VERSION "Toyota/Continental ARS510 radar bus (comma harness bus 1), frame-level. Object records need reassembly: see ars510/ and dbc/ars510_objects_vbus.dbc"

NS_ :

BS_:

BU_: RADAR CAMERA XXX

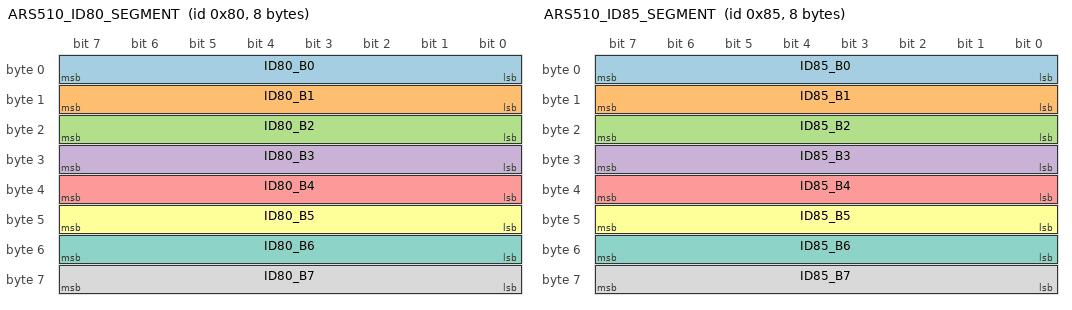
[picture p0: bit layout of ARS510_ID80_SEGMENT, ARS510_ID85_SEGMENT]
BO_ 128 ARS510_ID80_SEGMENT: 8 RADAR
 SG_ ID80_B0 : 0|8@1+ (1,0) [0|255] "raw" RADAR
 SG_ ID80_B1 : 8|8@1+ (1,0) [0|255] "raw" RADAR
 SG_ ID80_B2 : 16|8@1+ (1,0) [0|255] "raw" RADAR
 SG_ ID80_B3 : 24|8@1+ (1,0) [0|255] "raw" RADAR
 SG_ ID80_B4 : 32|8@1+ (1,0) [0|255] "raw" RADAR
 SG_ ID80_B5 : 40|8@1+ (1,0) [0|255] "raw" RADAR
 SG_ ID80_B6 : 48|8@1+ (1,0) [0|255] "raw" RADAR
 SG_ ID80_B7 : 56|8@1+ (1,0) [0|255] "raw" RADAR

BO_ 133 ARS510_ID85_SEGMENT: 8 RADAR
 SG_ ID85_B0 : 0|8@1+ (1,0) [0|255] "raw" RADAR
 SG_ ID85_B1 : 8|8@1+ (1,0) [0|255] "raw" RADAR
 SG_ ID85_B2 : 16|8@1+ (1,0) [0|255] "raw" RADAR
 SG_ ID85_B3 : 24|8@1+ (1,0) [0|255] "raw" RADAR
 SG_ ID85_B4 : 32|8@1+ (1,0) [0|255] "raw" RADAR
 SG_ ID85_B5 : 40|8@1+ (1,0) [0|255] "raw" RADAR
 SG_ ID85_B6 : 48|8@1+ (1,0) [0|255] "raw" RADAR
 SG_ ID85_B7 : 56|8@1+ (1,0) [0|255] "raw" RADAR

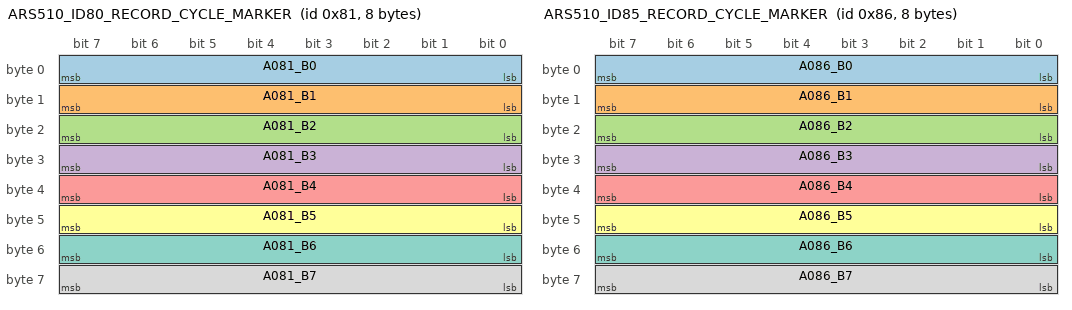
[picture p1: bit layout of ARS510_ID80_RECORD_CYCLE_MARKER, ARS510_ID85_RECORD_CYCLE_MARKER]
BO_ 129 ARS510_ID80_RECORD_CYCLE_MARKER: 8 CAMERA
 SG_ A081_B0 : 0|8@1+ (1,0) [0|255] "raw" RADAR
 SG_ A081_B1 : 8|8@1+ (1,0) [0|255] "raw" RADAR
 SG_ A081_B2 : 16|8@1+ (1,0) [0|255] "raw" RADAR
 SG_ A081_B3 : 24|8@1+ (1,0) [0|255] "raw" RADAR
 SG_ A081_B4 : 32|8@1+ (1,0) [0|255] "raw" RADAR
 SG_ A081_B5 : 40|8@1+ (1,0) [0|255] "raw" RADAR
 SG_ A081_B6 : 48|8@1+ (1,0) [0|255] "raw" RADAR
 SG_ A081_B7 : 56|8@1+ (1,0) [0|255] "raw" RADAR

BO_ 134 ARS510_ID85_RECORD_CYCLE_MARKER: 8 CAMERA
 SG_ A086_B0 : 0|8@1+ (1,0) [0|255] "raw" RADAR
 SG_ A086_B1 : 8|8@1+ (1,0) [0|255] "raw" RADAR
 SG_ A086_B2 : 16|8@1+ (1,0) [0|255] "raw" RADAR
 SG_ A086_B3 : 24|8@1+ (1,0) [0|255] "raw" RADAR
 SG_ A086_B4 : 32|8@1+ (1,0) [0|255] "raw" RADAR
 SG_ A086_B5 : 40|8@1+ (1,0) [0|255] "raw" RADAR
 SG_ A086_B6 : 48|8@1+ (1,0) [0|255] "raw" RADAR
 SG_ A086_B7 : 56|8@1+ (1,0) [0|255] "raw" RADAR

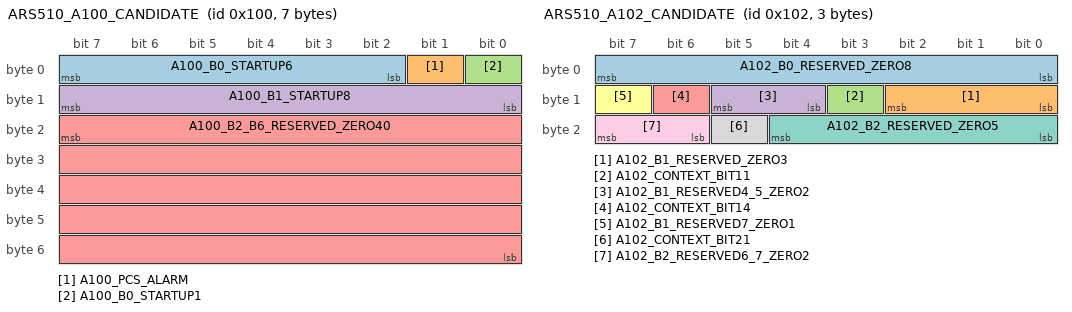
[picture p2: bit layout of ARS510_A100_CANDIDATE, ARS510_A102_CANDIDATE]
BO_ 256 ARS510_A100_CANDIDATE: 7 RADAR
 SG_ A100_B0_STARTUP6 : 7|6@0+ (1,0) [0|63] "raw" RADAR
 SG_ A100_PCS_ALARM : 1|1@0+ (1,0) [0|1] "" RADAR
 SG_ A100_B0_STARTUP1 : 0|1@0+ (1,0) [0|1] "raw" RADAR
 SG_ A100_B1_STARTUP8 : 15|8@0+ (1,0) [0|255] "raw" RADAR
 SG_ A100_B2_B6_RESERVED_ZERO40 : 23|40@0+ (1,0) [0|1099511627775] "raw" RADAR

BO_ 257 ARS510_A101_CANDIDATE: 6 CAMERA
 SG_ A101_STARTUP_STATE8 : 0|8@1+ (1,0) [0|255] "state" RADAR
 SG_ A101_B1_B5_RESERVED_ZERO40 : 15|40@0+ (1,0) [0|1099511627775] "raw" RADAR

BO_ 258 ARS510_A102_CANDIDATE: 3 CAMERA
 SG_ A102_B0_RESERVED_ZERO8 : 0|8@1+ (1,0) [0|255] "raw" RADAR
 SG_ A102_B1_RESERVED_ZERO3 : 8|3@1+ (1,0) [0|7] "raw" RADAR
 SG_ A102_CONTEXT_BIT11 : 11|1@1+ (1,0) [0|1] "state" RADAR
 SG_ A102_B1_RESERVED4_5_ZERO2 : 12|2@1+ (1,0) [0|3] "raw" RADAR
 SG_ A102_CONTEXT_BIT14 : 14|1@1+ (1,0) [0|1] "state" RADAR
 SG_ A102_B1_RESERVED7_ZERO1 : 15|1@1+ (1,0) [0|1] "raw" RADAR
 SG_ A102_B2_RESERVED_ZERO5 : 16|5@1+ (1,0) [0|31] "raw" RADAR
 SG_ A102_CONTEXT_BIT21 : 21|1@1+ (1,0) [0|1] "state" RADAR
 SG_ A102_B2_RESERVED6_7_ZERO2 : 22|2@1+ (1,0) [0|3] "raw" RADAR

BO_ 259 ARS510_A103_CANDIDATE: 2 RADAR
 SG_ A103_B0_RESERVED_ZERO8 : 0|8@1+ (1,0) [0|255] "raw" RADAR
 SG_ A103_B1_RESERVED_ZERO8 : 8|8@1+ (1,0) [0|255] "raw" RADAR

BO_ 384 ARS510_A180_CANDIDATE: 5 CAMERA
 SG_ A180_OBSERVED_CONSTANT_BE40 : 7|40@0+ (1,0) [0|1099511627775] "raw" RADAR

BO_ 400 ARS510_A190_CANDIDATE: 7 RADAR
 SG_ A190_STATUS_0_4 : 0|4@1+ (1,0) [0|15] "state" RADAR
 SG_ A190_B0_HIGH4 : 4|4@1+ (1,0) [0|15] "raw" RADAR
 SG_ A190_ACTIVE_SUMMARIES : 3|2@0+ (1,0) [0|3] "count" RADAR
 SG_ A190_B1 : 8|8@1+ (1,0) [0|255] "raw" RADAR
 SG_ A190_TIMESTAMP_US : 23|32@0+ (1,0) [0|4294967295] "us" RADAR
 SG_ A190_COUNTER_RESERVED0 : 48|4@1+ (1,0) [0|15] "raw" RADAR
 SG_ A190_COUNTER4 : 52|4@1+ (1,0) [0|15] "counter" RADAR

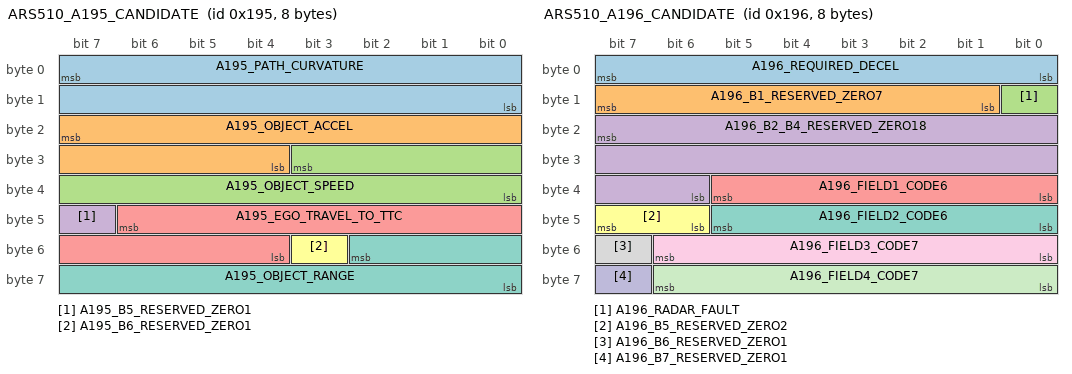
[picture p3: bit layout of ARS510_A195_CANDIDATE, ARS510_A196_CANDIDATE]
BO_ 405 ARS510_A195_CANDIDATE: 8 RADAR
 SG_ A195_PATH_CURVATURE : 7|16@0+ (7.5e-06,-0.24576) [-0.24576|0.2457525] "1/m" RADAR
 SG_ A195_OBJECT_ACCEL : 23|12@0+ (0.03125,-16) [-16|111.96875] "m/s^2" RADAR
 SG_ A195_OBJECT_SPEED : 27|12@0+ (0.0625,0) [0|255.9375] "m/s" RADAR
 SG_ A195_B5_RESERVED_ZERO1 : 47|1@0+ (1,0) [0|1] "raw" RADAR
 SG_ A195_EGO_TRAVEL_TO_TTC : 46|11@0+ (0.05,0) [0|102.35] "m" RADAR
 SG_ A195_B6_RESERVED_ZERO1 : 51|1@0+ (1,0) [0|1] "raw" RADAR
 SG_ A195_OBJECT_RANGE : 50|11@0+ (0.05,0) [0|102.35] "m" RADAR

BO_ 406 ARS510_A196_CANDIDATE: 8 RADAR
 SG_ A196_REQUIRED_DECEL : 7|8@0- (0.095,0) [-12.16|12.065] "m/s^2" RADAR
 SG_ A196_B1_RESERVED_ZERO7 : 15|7@0+ (1,0) [0|127] "raw" RADAR
 SG_ A196_RADAR_FAULT : 8|1@0+ (1,0) [0|1] "" RADAR
 SG_ A196_B2_B4_RESERVED_ZERO18 : 23|18@0+ (1,0) [0|262143] "raw" RADAR
 SG_ A196_FIELD1_CODE6 : 37|6@0+ (1,0) [0|63] "code" RADAR
 SG_ A196_B5_RESERVED_ZERO2 : 47|2@0+ (1,0) [0|3] "raw" RADAR
 SG_ A196_FIELD2_CODE6 : 45|6@0+ (1,0) [0|63] "code" RADAR
 SG_ A196_B6_RESERVED_ZERO1 : 55|1@0+ (1,0) [0|1] "raw" RADAR
 SG_ A196_FIELD3_CODE7 : 54|7@0+ (1,0) [0|127] "code" RADAR
 SG_ A196_B7_RESERVED_ZERO1 : 63|1@0+ (1,0) [0|1] "raw" RADAR
 SG_ A196_FIELD4_CODE7 : 62|7@0+ (1,0) [0|127] "code" RADAR

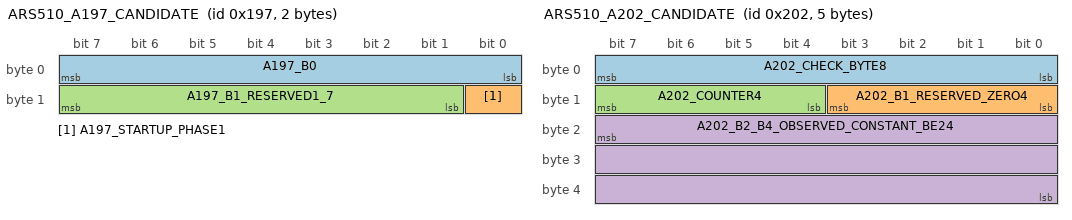
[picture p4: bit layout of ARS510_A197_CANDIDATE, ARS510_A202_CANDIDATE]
BO_ 407 ARS510_A197_CANDIDATE: 2 CAMERA
 SG_ A197_B0 : 0|8@1+ (1,0) [0|255] "raw" RADAR
 SG_ A197_STARTUP_PHASE1 : 8|1@1+ (1,0) [0|1] "state" RADAR
 SG_ A197_B1_RESERVED1_7 : 9|7@1+ (1,0) [0|127] "raw" RADAR

BO_ 408 ARS510_A198_CANDIDATE: 1 RADAR
 SG_ A198_OBSERVED_CONSTANT_BE8 : 7|8@0+ (1,0) [0|255] "raw" RADAR

BO_ 514 ARS510_A202_CANDIDATE: 5 RADAR
 SG_ A202_CHECK_BYTE8 : 0|8@1+ (1,0) [0|255] "debug" RADAR
 SG_ A202_B1_RESERVED_ZERO4 : 8|4@1+ (1,0) [0|15] "raw" RADAR
 SG_ A202_COUNTER4 : 12|4@1+ (1,0) [0|15] "counter" RADAR
 SG_ A202_B2_B4_OBSERVED_CONSTANT_BE24 : 23|24@0+ (1,0) [0|16777215] "raw" RADAR

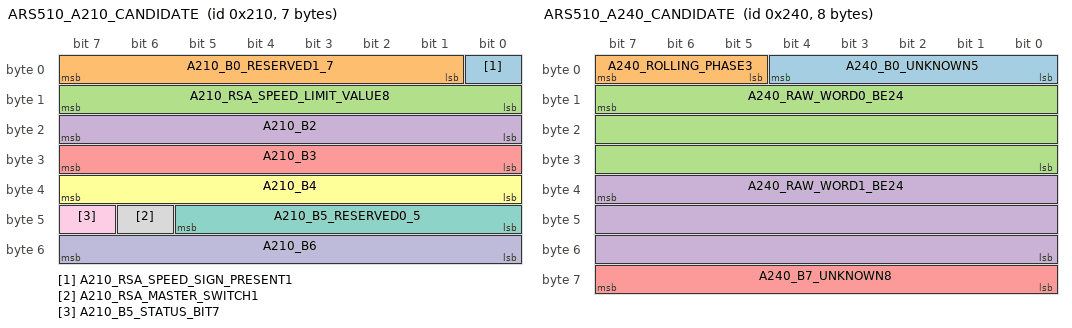
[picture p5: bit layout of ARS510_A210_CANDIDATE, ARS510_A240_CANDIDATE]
BO_ 528 ARS510_A210_CANDIDATE: 7 CAMERA
 SG_ A210_RSA_SPEED_SIGN_PRESENT1 : 0|1@1+ (1,0) [0|1] "state" RADAR
 SG_ A210_B0_RESERVED1_7 : 1|7@1+ (1,0) [0|127] "raw" RADAR
 SG_ A210_RSA_SPEED_LIMIT_VALUE8 : 8|8@1+ (1,0) [0|255] "display_speed" RADAR
 SG_ A210_B2 : 16|8@1+ (1,0) [0|255] "raw" RADAR
 SG_ A210_B3 : 24|8@1+ (1,0) [0|255] "raw" RADAR
 SG_ A210_B4 : 32|8@1+ (1,0) [0|255] "raw" RADAR
 SG_ A210_B5_RESERVED0_5 : 40|6@1+ (1,0) [0|63] "raw" RADAR
 SG_ A210_RSA_MASTER_SWITCH1 : 46|1@1+ (1,0) [0|1] "state" RADAR
 SG_ A210_B5_STATUS_BIT7 : 47|1@1+ (1,0) [0|1] "state" RADAR
 SG_ A210_B6 : 48|8@1+ (1,0) [0|255] "raw" RADAR

BO_ 576 ARS510_A240_CANDIDATE: 8 CAMERA
 SG_ A240_B0_UNKNOWN5 : 0|5@1+ (1,0) [0|31] "raw" RADAR
 SG_ A240_ROLLING_PHASE3 : 5|3@1+ (1,0) [0|7] "state" RADAR
 SG_ A240_RAW_WORD0_BE24 : 15|24@0+ (1,0) [0|16777215] "raw" RADAR
 SG_ A240_RAW_WORD1_BE24 : 39|24@0+ (1,0) [0|16777215] "raw" RADAR
 SG_ A240_B7_UNKNOWN8 : 56|8@1+ (1,0) [0|255] "raw" RADAR

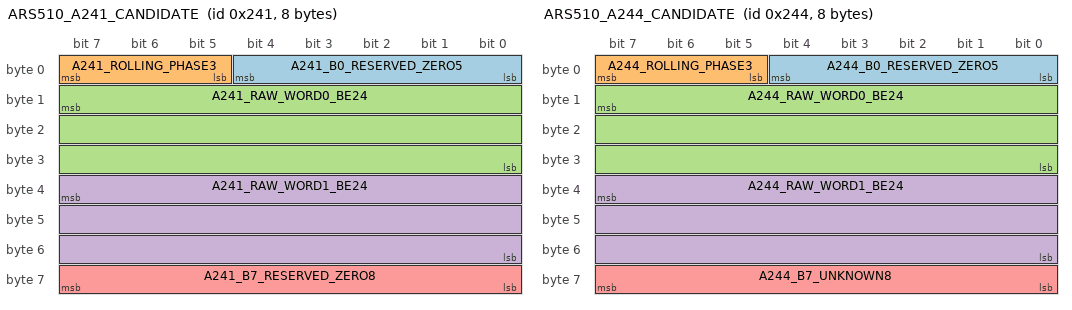
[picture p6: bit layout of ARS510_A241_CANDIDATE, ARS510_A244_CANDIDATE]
BO_ 577 ARS510_A241_CANDIDATE: 8 CAMERA
 SG_ A241_B0_RESERVED_ZERO5 : 0|5@1+ (1,0) [0|31] "raw" RADAR
 SG_ A241_ROLLING_PHASE3 : 5|3@1+ (1,0) [0|7] "state" RADAR
 SG_ A241_RAW_WORD0_BE24 : 15|24@0+ (1,0) [0|16777215] "raw" RADAR
 SG_ A241_RAW_WORD1_BE24 : 39|24@0+ (1,0) [0|16777215] "raw" RADAR
 SG_ A241_B7_RESERVED_ZERO8 : 56|8@1+ (1,0) [0|255] "raw" RADAR

BO_ 580 ARS510_A244_CANDIDATE: 8 CAMERA
 SG_ A244_B0_RESERVED_ZERO5 : 0|5@1+ (1,0) [0|31] "raw" RADAR
 SG_ A244_ROLLING_PHASE3 : 5|3@1+ (1,0) [0|7] "state" RADAR
 SG_ A244_RAW_WORD0_BE24 : 15|24@0+ (1,0) [0|16777215] "raw" RADAR
 SG_ A244_RAW_WORD1_BE24 : 39|24@0+ (1,0) [0|16777215] "raw" RADAR
 SG_ A244_B7_UNKNOWN8 : 56|8@1+ (1,0) [0|255] "raw" RADAR

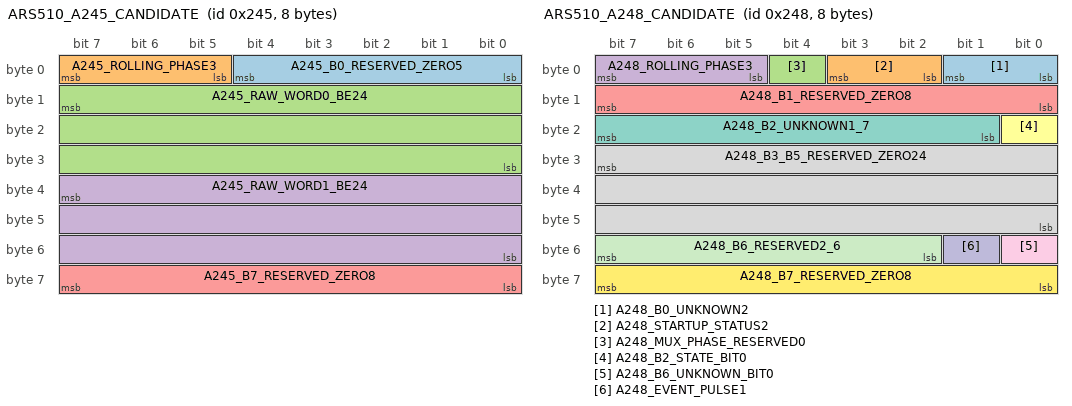
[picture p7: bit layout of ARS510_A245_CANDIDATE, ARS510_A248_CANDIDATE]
BO_ 581 ARS510_A245_CANDIDATE: 8 CAMERA
 SG_ A245_B0_RESERVED_ZERO5 : 0|5@1+ (1,0) [0|31] "raw" RADAR
 SG_ A245_ROLLING_PHASE3 : 5|3@1+ (1,0) [0|7] "state" RADAR
 SG_ A245_RAW_WORD0_BE24 : 15|24@0+ (1,0) [0|16777215] "raw" RADAR
 SG_ A245_RAW_WORD1_BE24 : 39|24@0+ (1,0) [0|16777215] "raw" RADAR
 SG_ A245_B7_RESERVED_ZERO8 : 56|8@1+ (1,0) [0|255] "raw" RADAR

BO_ 584 ARS510_A248_CANDIDATE: 8 CAMERA
 SG_ A248_B0_UNKNOWN2 : 0|2@1+ (1,0) [0|3] "raw" RADAR
 SG_ A248_STARTUP_STATUS2 : 2|2@1+ (1,0) [0|3] "state" RADAR
 SG_ A248_MUX_PHASE_RESERVED0 : 4|1@1+ (1,0) [0|1] "raw" RADAR
 SG_ A248_ROLLING_PHASE3 : 5|3@1+ (1,0) [0|7] "state" RADAR
 SG_ A248_B1_RESERVED_ZERO8 : 8|8@1+ (1,0) [0|255] "raw" RADAR
 SG_ A248_B2_STATE_BIT0 : 16|1@1+ (1,0) [0|1] "state" RADAR
 SG_ A248_B2_UNKNOWN1_7 : 17|7@1+ (1,0) [0|127] "raw" RADAR
 SG_ A248_B3_B5_RESERVED_ZERO24 : 31|24@0+ (1,0) [0|16777215] "raw" RADAR
 SG_ A248_B6_UNKNOWN_BIT0 : 48|1@1+ (1,0) [0|1] "raw" RADAR
 SG_ A248_EVENT_PULSE1 : 49|1@1+ (1,0) [0|1] "state" RADAR
 SG_ A248_B6_RESERVED2_6 : 50|6@1+ (1,0) [0|63] "raw" RADAR
 SG_ A248_B7_RESERVED_ZERO8 : 56|8@1+ (1,0) [0|255] "raw" RADAR

BO_ 589 ARS510_A24D_CANDIDATE: 7 CAMERA
 SG_ A24D_OBSERVED_CONSTANT_BE56 : 7|56@0+ (1,0) [0|72057594037927935] "raw" RADAR

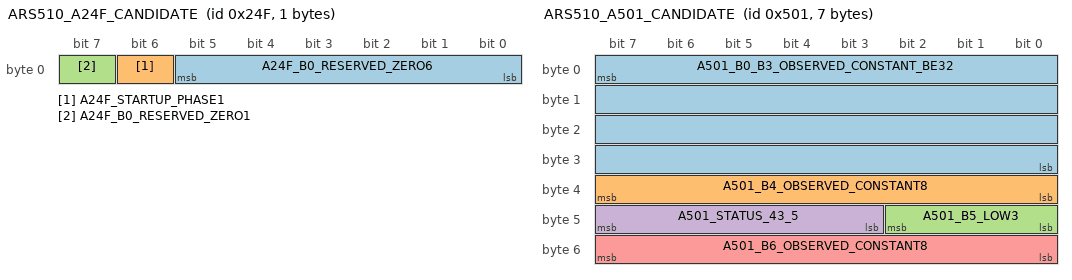
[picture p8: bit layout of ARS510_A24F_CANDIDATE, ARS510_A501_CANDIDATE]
BO_ 591 ARS510_A24F_CANDIDATE: 1 RADAR
 SG_ A24F_B0_RESERVED_ZERO6 : 0|6@1+ (1,0) [0|63] "raw" RADAR
 SG_ A24F_STARTUP_PHASE1 : 6|1@1+ (1,0) [0|1] "state" RADAR
 SG_ A24F_B0_RESERVED_ZERO1 : 7|1@1+ (1,0) [0|1] "raw" RADAR

BO_ 1280 ARS510_A500_CANDIDATE: 6 CAMERA
 SG_ A500_OBSERVED_CONSTANT_BE48 : 7|48@0+ (1,0) [0|281474976710655] "raw" RADAR

BO_ 1281 ARS510_A501_CANDIDATE: 7 CAMERA
 SG_ A501_B0_B3_OBSERVED_CONSTANT_BE32 : 7|32@0+ (1,0) [0|4294967295] "raw" RADAR
 SG_ A501_B4_OBSERVED_CONSTANT8 : 32|8@1+ (1,0) [0|255] "raw" RADAR
 SG_ A501_B5_LOW3 : 40|3@1+ (1,0) [0|7] "raw" RADAR
 SG_ A501_STATUS_43_5 : 43|5@1+ (1,0) [0|31] "code" RADAR
 SG_ A501_B6_OBSERVED_CONSTANT8 : 48|8@1+ (1,0) [0|255] "raw" RADAR

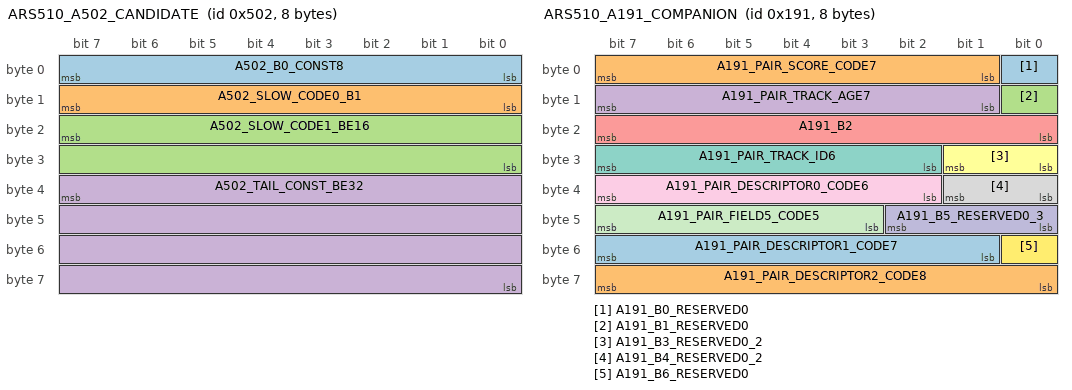
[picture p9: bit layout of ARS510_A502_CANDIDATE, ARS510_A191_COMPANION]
BO_ 1282 ARS510_A502_CANDIDATE: 8 RADAR
 SG_ A502_B0_CONST8 : 0|8@1+ (1,0) [0|255] "raw" RADAR
 SG_ A502_SLOW_CODE0_B1 : 8|8@1+ (1,0) [0|255] "raw" RADAR
 SG_ A502_SLOW_CODE1_BE16 : 23|16@0+ (1,0) [0|65535] "raw" RADAR
 SG_ A502_TAIL_CONST_BE32 : 39|32@0+ (1,0) [0|4294967295] "raw" RADAR

BO_ 1664 ARS510_A680_OBJECT: 8 RADAR
 SG_ A680_SELECTOR : 7|8@0+ (1,0) [0|255] "code" RADAR
 SG_ A680_LONG_DIST : 15|13@0+ (0.03125,0) [0|255.97] "m" RADAR
 SG_ A680_LAT_DIST : 18|11@0- (0.015,0) [-15.36|15.345] "m" RADAR
 SG_ A680_SPEED_OVER_GROUND : 39|10@0+ (0.15,-76.8) [-76.8|76.65] "m/s" RADAR
 SG_ A680_FLAGS : 45|6@0+ (1,0) [0|63] "raw" RADAR
 SG_ A680_STATIONARY : 40|1@0+ (1,0) [0|1] "" RADAR
 SG_ A680_ONCOMING : 41|1@0+ (1,0) [0|1] "" RADAR
 SG_ A680_SEEN_MOVING : 43|1@0+ (1,0) [0|1] "" RADAR
 SG_ A680_LAT_SPEED_CODE : 55|8@0+ (1,-128) [-128|127] "code" RADAR
 SG_ A680_B7_HIGH4 : 63|4@0+ (1,0) [0|15] "raw" RADAR
 SG_ A680_B7_LOW4 : 59|4@0+ (1,0) [0|15] "raw" RADAR

BO_ 401 ARS510_A191_COMPANION: 8 RADAR
 SG_ A191_B0_RESERVED0 : 0|1@1+ (1,0) [0|1] "raw" RADAR
 SG_ A191_PAIR_SCORE_CODE7 : 1|7@1+ (1,0) [0|127] "code" RADAR
 SG_ A191_B1_RESERVED0 : 8|1@1+ (1,0) [0|1] "raw" RADAR
 SG_ A191_PAIR_TRACK_AGE7 : 9|7@1+ (1,0) [0|127] "radar_cycle" RADAR
 SG_ A191_B2 : 16|8@1+ (1,0) [0|255] "raw" RADAR
 SG_ A191_B3_RESERVED0_2 : 24|2@1+ (1,0) [0|3] "raw" RADAR
 SG_ A191_PAIR_TRACK_ID6 : 26|6@1+ (1,0) [0|63] "code" RADAR
 SG_ A191_B4_RESERVED0_2 : 32|2@1+ (1,0) [0|3] "raw" RADAR
 SG_ A191_PAIR_DESCRIPTOR0_CODE6 : 34|6@1+ (0.1,0) [0|6.3] "m" RADAR
 SG_ A191_B5_RESERVED0_3 : 40|3@1+ (1,0) [0|7] "raw" RADAR
 SG_ A191_PAIR_FIELD5_CODE5 : 43|5@1+ (1,0) [0|31] "code" RADAR
 SG_ A191_B6_RESERVED0 : 48|1@1+ (1,0) [0|1] "raw" RADAR
 SG_ A191_PAIR_DESCRIPTOR1_CODE7 : 49|7@1+ (0.1,0) [0|12.7] "m" RADAR
 SG_ A191_PAIR_DESCRIPTOR2_CODE8 : 56|8@1+ (0.1,0) [0|25.5] "m" RADAR

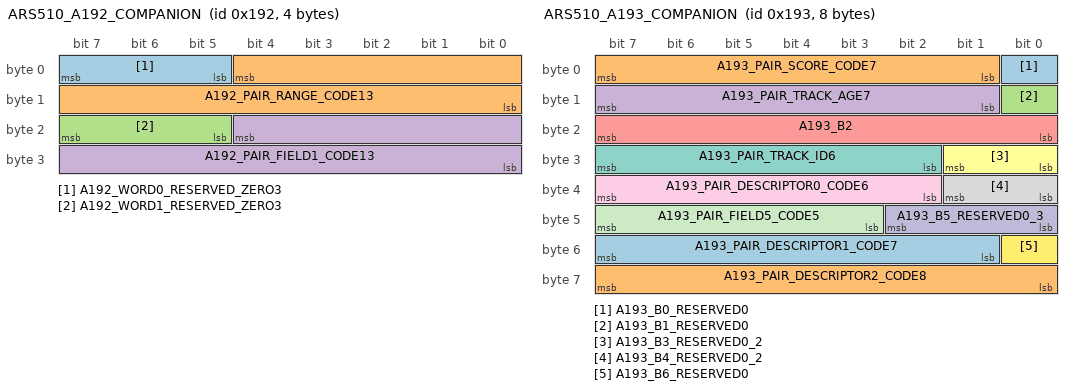
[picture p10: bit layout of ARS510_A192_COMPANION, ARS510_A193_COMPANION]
BO_ 402 ARS510_A192_COMPANION: 4 RADAR
 SG_ A192_WORD0_RESERVED_ZERO3 : 5|3@1+ (1,0) [0|7] "raw" RADAR
 SG_ A192_PAIR_RANGE_CODE13 : 4|13@0+ (0.0625,-10) [-10|501.94] "m" RADAR
 SG_ A192_WORD1_RESERVED_ZERO3 : 21|3@1+ (1,0) [0|7] "raw" RADAR
 SG_ A192_PAIR_FIELD1_CODE13 : 20|13@0+ (0.015,-30.72) [-30.72|92.145] "m" RADAR

BO_ 403 ARS510_A193_COMPANION: 8 RADAR
 SG_ A193_B0_RESERVED0 : 0|1@1+ (1,0) [0|1] "raw" RADAR
 SG_ A193_PAIR_SCORE_CODE7 : 1|7@1+ (1,0) [0|127] "code" RADAR
 SG_ A193_B1_RESERVED0 : 8|1@1+ (1,0) [0|1] "raw" RADAR
 SG_ A193_PAIR_TRACK_AGE7 : 9|7@1+ (1,0) [0|127] "radar_cycle" RADAR
 SG_ A193_B2 : 16|8@1+ (1,0) [0|255] "raw" RADAR
 SG_ A193_B3_RESERVED0_2 : 24|2@1+ (1,0) [0|3] "raw" RADAR
 SG_ A193_PAIR_TRACK_ID6 : 26|6@1+ (1,0) [0|63] "code" RADAR
 SG_ A193_B4_RESERVED0_2 : 32|2@1+ (1,0) [0|3] "raw" RADAR
 SG_ A193_PAIR_DESCRIPTOR0_CODE6 : 34|6@1+ (0.1,0) [0|6.3] "m" RADAR
 SG_ A193_B5_RESERVED0_3 : 40|3@1+ (1,0) [0|7] "raw" RADAR
 SG_ A193_PAIR_FIELD5_CODE5 : 43|5@1+ (1,0) [0|31] "code" RADAR
 SG_ A193_B6_RESERVED0 : 48|1@1+ (1,0) [0|1] "raw" RADAR
 SG_ A193_PAIR_DESCRIPTOR1_CODE7 : 49|7@1+ (0.1,0) [0|12.7] "m" RADAR
 SG_ A193_PAIR_DESCRIPTOR2_CODE8 : 56|8@1+ (0.1,0) [0|25.5] "m" RADAR

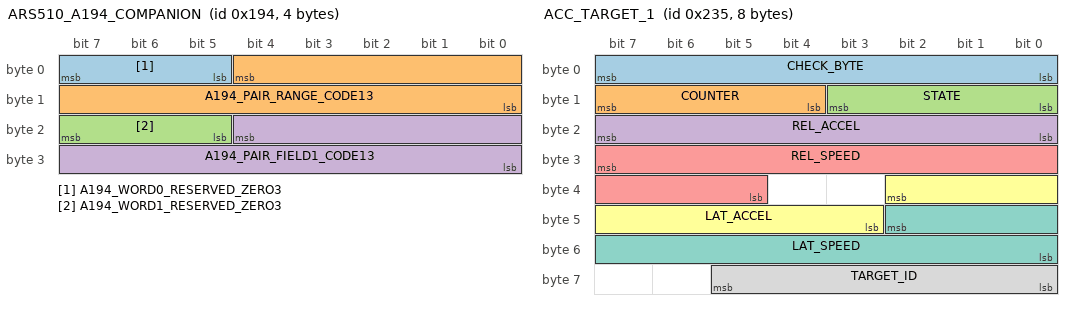
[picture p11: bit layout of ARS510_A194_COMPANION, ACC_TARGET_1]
BO_ 404 ARS510_A194_COMPANION: 4 RADAR
 SG_ A194_WORD0_RESERVED_ZERO3 : 5|3@1+ (1,0) [0|7] "raw" RADAR
 SG_ A194_PAIR_RANGE_CODE13 : 4|13@0+ (0.0625,-10) [-10|501.94] "m" RADAR
 SG_ A194_WORD1_RESERVED_ZERO3 : 21|3@1+ (1,0) [0|7] "raw" RADAR
 SG_ A194_PAIR_FIELD1_CODE13 : 20|13@0+ (0.015,-30.72) [-30.72|92.145] "m" RADAR

BO_ 565 ACC_TARGET_1: 8 RADAR
 SG_ CHECK_BYTE : 7|8@0+ (1,0) [0|255] "" RADAR
 SG_ COUNTER : 15|4@0+ (1,0) [0|15] "" RADAR
 SG_ STATE : 11|4@0+ (1,0) [0|15] "" RADAR
 SG_ REL_ACCEL : 23|8@0+ (0.125,-12.5) [-12.5|19.375] "m/s^2" RADAR
 SG_ REL_SPEED : 31|11@0+ (0.125,-128) [-128|127.875] "m/s" RADAR
 SG_ LAT_ACCEL : 34|8@0+ (0.125,-12.5) [-12.5|19.375] "m/s^2" RADAR
 SG_ LAT_SPEED : 42|11@0+ (0.0125,-12.8) [-12.8|12.7875] "m/s" RADAR
 SG_ TARGET_ID : 61|6@0+ (1,0) [0|63] "" RADAR

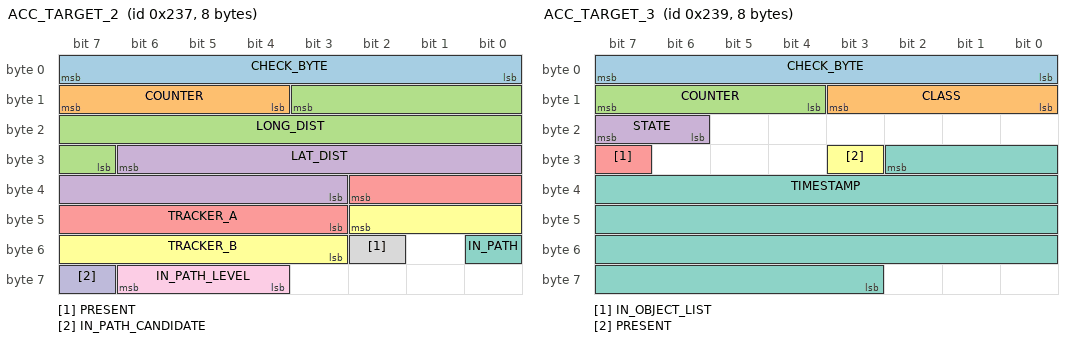
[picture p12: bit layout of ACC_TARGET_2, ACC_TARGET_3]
BO_ 567 ACC_TARGET_2: 8 RADAR
 SG_ CHECK_BYTE : 7|8@0+ (1,0) [0|255] "" RADAR
 SG_ COUNTER : 15|4@0+ (1,0) [0|15] "" RADAR
 SG_ LONG_DIST : 11|13@0+ (0.025,0) [0|204.775] "m" RADAR
 SG_ LAT_DIST : 30|12@0+ (0.01,-20) [-20|20.95] "m" RADAR
 SG_ TRACKER_A : 34|8@0+ (1,0) [0|255] "" RADAR
 SG_ TRACKER_B : 42|8@0+ (1,0) [0|255] "" RADAR
 SG_ IN_PATH : 48|1@0+ (1,0) [0|1] "" RADAR
 SG_ PRESENT : 50|1@0+ (1,0) [0|1] "" RADAR
 SG_ IN_PATH_LEVEL : 62|3@0+ (1,0) [0|7] "" RADAR
 SG_ IN_PATH_CANDIDATE : 63|1@0+ (1,0) [0|1] "" RADAR

BO_ 569 ACC_TARGET_3: 8 RADAR
 SG_ CHECK_BYTE : 7|8@0+ (1,0) [0|255] "" RADAR
 SG_ CLASS : 11|4@0+ (1,0) [0|15] "" RADAR
 SG_ COUNTER : 15|4@0+ (1,0) [0|15] "" RADAR
 SG_ STATE : 23|2@0+ (1,0) [0|3] "" RADAR
 SG_ IN_OBJECT_LIST : 31|1@0+ (1,0) [0|1] "" RADAR
 SG_ PRESENT : 27|1@0+ (1,0) [0|1] "" RADAR
 SG_ TIMESTAMP : 26|32@0+ (1,0) [0|4294967295] "us" RADAR

BO_ 571 ARS510_A23B_COMPANION: 3 RADAR
 SG_ A23B_B0_CHECK_BYTE : 0|8@1+ (1,0) [0|255] "debug" RADAR
 SG_ A23B_STATUS_MUX4 : 8|4@1+ (1,0) [0|15] "state" RADAR
 SG_ A23B_COUNTER4 : 12|4@1+ (1,0) [0|15] "counter" RADAR
 SG_ A23B_B2 : 16|8@1+ (1,0) [0|255] "raw" RADAR
 SG_ A23B_TARGET_WIDTH_CM : 11|12@0+ (1,0) [0|4095] "cm" RADAR

BO_ 573 ARS510_A23D_COMPANION: 8 RADAR
 SG_ A23D_OBSERVED_CONSTANT_BE64 : 7|64@0+ (1,0) [0|18446744073709551615] "raw" RADAR

CM_ "ARS510 radar bus (comma harness bus 1), frame-local view. The 0x80 object list and 0x85 metadata record are segmented over many frames and are reassembled in code (ars510.transport); their frames appear here only as raw bytes. Decoded objects are in ars510_objects_vbus.dbc. Documentation: github.com/ds-sebastian/ars510-radar docs/.";
CM_ BO_ 128 "0x80 object-list transport: a 742-byte record (20 object slots + CRC32) sent every 60 ms as 106 ISO-TP-like frames. First frame starts 12 E4; bytes 1-7 of each frame are appended.";
CM_ BO_ 133 "0x85 metadata-record transport: a 147-byte record (prefix, ten 12-byte cells, CRC32) sent every 60 ms as 21 frames. First frame starts 10 90.";
CM_ BO_ 129 "ISO-TP flow control for each 0x80 transfer: 30 00 00 00 00 00 00 00 (clear to send, block size 0, STmin 0) about 0.35 ms after the first frame; the radar sends the consecutive frames only after it. Sender inferred: the transfer's receiver, the camera.";
CM_ BO_ 134 "ISO-TP flow control for each 0x85 transfer: 30 00 00 00 00 00 00 00 (clear to send, block size 0, STmin 0) about 0.35 ms after the first frame; the radar sends the consecutive frames only after it. Sender inferred: the transfer's receiver, the camera.";
CM_ BO_ 256 "Startup context: word 0 is 0xFFFF in the first frame after power-up, zero afterwards; byte 0 = 0x02 during a PCS alarm.";
CM_ BO_ 257 "Camera-sent radar-running state: 0x1D while the radar boots, 0x11 once its object list arrives (switches 60 ms before 0x197 bit 8 sets); the C-HR camera sends 0x15 instead of 0x11.";
CM_ BO_ 258 "Camera-sent status bits: 11 = LKAS_HUD LDA_UNAVAILABLE copy, 14 = close-following state relayed by the radar into 0x366, 21 = EPS lane-keeping unavailable.";
CM_ BO_ 259 "Always zero.";
CM_ BO_ 384 "Constant CF C0 00 00 00.";
CM_ BO_ 400 "Radar cycle header (16.7 Hz): number of target summaries, microsecond timestamp and a mod-16 cycle counter.";
CM_ BO_ 401 "Selected-target companion A (with 0x192): score, age and track code of a target the radar selects itself. Sentinel FE FE FE FC FC FF FE FF = idle.";
CM_ BO_ 402 "Selected-target summary A (4 bytes): distance and lateral position of one target of the radar's internal tracker, in the object list's encoding. Sentinel 00 FF 00 FF = idle.";
CM_ BO_ 403 "Selected-target companion B (with 0x194); same layout as 0x191.";
CM_ BO_ 404 "Selected-target summary B; same layout as 0x192.";
CM_ BO_ 405 "Event frame, paired with 0x196: exact idle payload on 99.67% of frames; non-idle in a short-time-to-collision state (docs/05).";
CM_ BO_ 406 "Event frame, paired with 0x195. Bytes 4-7 (FIELD1-4 with their neighbouring raw bits): byte 6 - byte 4 and byte 7 - byte 5 are the lateral distances from the event object to the left / right edge of a corridor about 1.0-1.15 m either side of the predicted ego path, about 0.1 m per code (likely on the owner car, not confirmed on a second car); bytes 4 / 5 clip at 50.";
CM_ BO_ 407 "Camera-sent boot flag: bit 8 sets about 0.2 s after the first object record and stays set, also through object-list outages (the camera's acknowledgement of the first record, not live radar health).";
CM_ BO_ 408 "Status byte: 0x10; 0x90 (bit 7) while 0x196 A196_RADAR_FAULT is set.";
CM_ BO_ 514 "Counter frame: byte 1 high nibble counts mod 16; byte 0 is a check byte that depends only on the counter.";
CM_ BO_ 528 "Copy of Toyota road-sign-assist data (speed-sign presence, speed-limit value, TSR switch).";
CM_ BO_ 565 "The radar's ACC target, 50 Hz (content per 60 ms radar cycle): closing speed, relative acceleration, lateral speed and acceleration and the target ID. Position and in-path state are on 0x237.";
CM_ SG_ 565 REL_SPEED "Closing speed of the ACC target, m/s, negative = closing; 0.125 m/s per code (stopped leads, distance slope).";
CM_ SG_ 565 REL_ACCEL "Relative acceleration of the ACC target (positive = opening): (code - 100) * 0.125 m/s^2; one code is one speed code per second (closure 1.00 over 2 s windows). Code 100 is the idle value.";
CM_ SG_ 565 LAT_SPEED "Lateral speed of the ACC target relative to ego in the rotating ego frame, left positive, about 0.0125 m/s per code (the lateral position changes by 0.98-1.00 x this speed; stationary targets read about -1.1 to -1.2 x yaw rate x distance). Wraps above +12.79 m/s (crossing traffic); the check byte then differs by 0x9C.";
CM_ SG_ 565 LAT_ACCEL "Relative lateral acceleration of the ACC target, left positive: (code - 100) * 0.125 m/s^2 (nominal unit, as the longitudinal field). Mostly minus the ego lateral acceleration (-8.2 codes per m/s^2), plus a lateral-speed term; lags the yaw rate.";
CM_ SG_ 565 TARGET_ID "The radar tracker's track number, 6 bits (byte 7 bits 5-0): constant while the radar follows one target and kept when it re-acquires the same track; 32-63 are in use on a C-HR 2021 radar (8821FF410300), the RAV4 radars sent 0-31; 63 with the idle payload (read idle from STATE). The 0x680 object is the same car as this target when the number is 0. Byte 7 bits 7-6 are 0 with a target, 3 idle.";
CM_ SG_ 569 STATE "Byte 2 bits 6-7: 1 with an ACC target, 2 idle.";
CM_ BO_ 567 "The radar's ACC target, 50 Hz: distance, lateral position, in-path state and two tracker bytes (see 0x235).";
CM_ SG_ 567 LAT_DIST "Lateral position of the ACC target, m, left positive: 12 bits, (code - 2000) * 0.01. One object-list lateral code is 1.5 of these codes (1.499-1.502 on five sets). Wraps above +20.95 m (turning / junction targets 21-53 m to the left, about 8 cycles per hour; the check byte then differs by 0x14) and stops at -20.00 m.";
CM_ SG_ 567 TRACKER_A "Raw tracker byte: 35-36 on a steady target, 44-50 while it accelerates, a median of 48-74 while it brakes.";
CM_ SG_ 567 TRACKER_B "Tracker byte: the TRACKER_A quantity at a finer scale; 2.5 x TRACKER_A (+-1) for a stopped target, 3.7-4.3 x for a mover (growing with range); rises toward 240 and wraps while the target accelerates or brakes.";
CM_ SG_ 567 PRESENT "1 with an ACC target.";
CM_ SG_ 567 IN_PATH "1 while the target is confirmed in the path (level 5).";
CM_ SG_ 567 IN_PATH_CANDIDATE "1 while the target is a candidate (levels 4-2).";
CM_ SG_ 567 IN_PATH_LEVEL "In-path level 5, 4, 3, 2; steps to the neighbouring level only; lower levels sit farther from the path.";
CM_ SG_ 567 LONG_DIST "Distance of the ACC target, 0.025 m per code, zero offset (0.02 m median residual against the 0x680 object range).";
CM_ BO_ 569 "ACC target, part 3, 50 Hz: target class, object-list flag and the radar cycle clock of the 0x235 / 0x237 content (upstream DBC: TIMESTAMP only).";
CM_ BO_ 571 "50 Hz companion of the ACC target (3 bytes): CRC-8, counter and the target width in cm.";
CM_ BO_ 573 "Always zero.";
CM_ BO_ 576 "Context frame, 16.7 Hz, rolling phase 1-7 in byte 0. At night carries light-source records (two per frame, paired with 0x244); default body by day.";
CM_ BO_ 577 "Context frame, 16.7 Hz, rolling phase 1-7 in byte 0; default body.";
CM_ BO_ 580 "Context frame, 16.7 Hz, rolling phase 1-7 in byte 0. At night carries light-source records (two per frame, paired with 0x240); bytes 4 and 7 are always equal.";
CM_ BO_ 581 "Context frame, 16.7 Hz, rolling phase 1-7 in byte 0; default body.";
CM_ BO_ 584 "Startup / event context frame with the same rolling phase as 0x240-0x245.";
CM_ BO_ 589 "State frame: 00 00 00 00 00 00 56 normally. Byte 4 copies the camera's auto-high-beam status (0x414 C_AHB = 1, seen in heavy rain): 00 00 00 00 02 00 58.";
CM_ BO_ 591 "Startup phase: bit 6 sets once the radar is running.";
CM_ BO_ 1280 "Regular payload shared by the three recorded cars.";
CM_ BO_ 1281 "Slow status frame: constants plus one five-bit code at bit 43; byte 5 low three bits are 4 during active output and 0 at startup.";
CM_ BO_ 1282 "Slow frame (every 3 s): two driving-updated codes (bytes 1 and 2-3), held at settled standstill, and a constant tail that differs between recorded cars (redacted).";
CM_ BO_ 1664 "The function-level tracker's track number 0 (2 Hz): the same car as the ACC target when its TARGET_ID is 0, otherwise mostly a stationary roadside object. Idle payload 00 00 08 00 80 00 80 0A.";
CM_ SG_ 514 A202_CHECK_BYTE8 "Check byte, a fixed function of A202_COUNTER4: 0:10 1:8D 2:37 3:AA 4:5E 5:C3 6:79 7:E4 8:8C 9:11 10:AB 11:36 12:C2 13:5F 14:E5 15:78 (hex).";
CM_ SG_ 514 A202_B1_RESERVED_ZERO4 "Zero, apart from the rare all-ones (FF ...) frames.";
CM_ SG_ 514 A202_B2_B4_OBSERVED_CONSTANT_BE24 "Constant 0x036D80, apart from the rare all-ones (FF ...) frames.";
CM_ SG_ 591 A24F_B0_RESERVED_ZERO6 "Always zero.";
CM_ SG_ 591 A24F_STARTUP_PHASE1 "0 while the radar starts up, 1 once running (stays 1).";
CM_ SG_ 591 A24F_B0_RESERVED_ZERO1 "0 on the RAV4s and the C-HRs. On the Yaris it switches with A24F_STARTUP_PHASE1: 0 at boot, 1 once running (byte 0 goes 0x00 -> 0xC0), a second running flag on that radar.";
CM_ SG_ 1281 A501_B0_B3_OBSERVED_CONSTANT_BE32 "Constant 0xFFF0FFF0.";
CM_ SG_ 1281 A501_B4_OBSERVED_CONSTANT8 "Constant 0x70; 0xFF in the power-up frame.";
CM_ SG_ 1281 A501_B6_OBSERVED_CONSTANT8 "Constant 0x00.";
CM_ SG_ 384 A180_OBSERVED_CONSTANT_BE40 "Constant 0xCFC0000000; 0xFFC0000000 on the first frame after power-up.";
CM_ SG_ 408 A198_OBSERVED_CONSTANT_BE8 "0x10 normally; 0x90 (bit 7 set) together with the 0x196 radar fault flag (two object-list outages on the second car).";
CM_ SG_ 573 A23D_OBSERVED_CONSTANT_BE64 "Always zero.";
CM_ SG_ 589 A24D_OBSERVED_CONSTANT_BE56 "00000000000056 normally; 00000000020058 in a rare second state.";
CM_ SG_ 1280 A500_OBSERVED_CONSTANT_BE48 "One regular payload, identical on the three recorded cars (a few rare variants and a start-up body), so not a unit identifier.";
CM_ SG_ 405 A195_PATH_CURVATURE "Ego path curvature, left positive, about 1/133,000 per m per code around 32768 (R2 0.997 against yaw rate / speed); 32766 when idle.";
CM_ SG_ 405 A195_OBJECT_ACCEL "Over-ground acceleration of the 0x195 object, about 1/32 m/s2 per code (29-32 codes per m/s2 measured) around 512; 510 when idle. Its low 10 bits are the older 10-bit event code.";
CM_ SG_ 405 A195_OBJECT_SPEED "Longitudinal over-ground speed of the 0x195 object (including the ego-rotation term), 1/16 m/s per code, zero code 0. Like the ACC target it matches carState about 0.15 s earlier.";
CM_ SG_ 405 A195_B5_RESERVED_ZERO1 "Zero, apart from the rare all-ones (FF ...) frames.";
CM_ SG_ 405 A195_EGO_TRAVEL_TO_TTC "Ego predicted travel until the time to collision with the 0x195 object (v T + a T2 / 2, T = range / closing speed), clamped at 0.";
CM_ SG_ 405 A195_B6_RESERVED_ZERO1 "Zero, apart from the rare all-ones (FF ...) frames.";
CM_ SG_ 405 A195_OBJECT_RANGE "Range of one radar-tracker object while the event pair is active (0 when idle): floor(ACC distance code / 2) on the ACC car; otherwise another, mostly stationary object.";
CM_ SG_ 406 A196_REQUIRED_DECEL "Required deceleration for the event object while active: floor(a_req / 0.095) of a lead-moving / lead-stops formula with a 1.75 m margin and an ego speed 0.15 s old; -1 when idle.";
CM_ SG_ 406 A196_B1_RESERVED_ZERO7 "Zero, apart from the rare all-ones (FF ...) frames.";
CM_ SG_ 406 A196_RADAR_FAULT "Radar fault: held while the radar declares itself blocked (car-bus 0x411 dust state; the object list keeps running) and after some object-list outages; also set for the single first cycle after power-up, so require two or more consecutive cycles (likely).";
CM_ SG_ 406 A196_B2_B4_RESERVED_ZERO18 "Zero, apart from the rare all-ones (FF ...) frames.";
CM_ SG_ 406 A196_FIELD1_CODE6 "Raw.";
CM_ SG_ 406 A196_B5_RESERVED_ZERO2 "Zero, apart from the rare all-ones (FF ...) frames.";
CM_ SG_ 406 A196_FIELD2_CODE6 "Raw; byte 5 bits 0-5 (reaches 50; bit 5 is set on about 20 % of active frames).";
CM_ SG_ 406 A196_B6_RESERVED_ZERO1 "Zero, apart from the rare all-ones (FF ...) frames.";
CM_ SG_ 406 A196_FIELD3_CODE7 "Raw.";
CM_ SG_ 406 A196_B7_RESERVED_ZERO1 "Zero, apart from the rare all-ones (FF ...) frames.";
CM_ SG_ 406 A196_FIELD4_CODE7 "Raw; byte 7 bits 0-6 (reaches 74-80; bit 6 is set on about 5 % of active frames).";
CM_ SG_ 128 ID80_B0 "Raw transport byte 0 of the segmented 0x80 record.";
CM_ SG_ 128 ID80_B1 "Raw transport byte 1 of the segmented 0x80 record.";
CM_ SG_ 128 ID80_B2 "Raw transport byte 2 of the segmented 0x80 record.";
CM_ SG_ 128 ID80_B3 "Raw transport byte 3 of the segmented 0x80 record.";
CM_ SG_ 128 ID80_B4 "Raw transport byte 4 of the segmented 0x80 record.";
CM_ SG_ 128 ID80_B5 "Raw transport byte 5 of the segmented 0x80 record.";
CM_ SG_ 128 ID80_B6 "Raw transport byte 6 of the segmented 0x80 record.";
CM_ SG_ 128 ID80_B7 "Raw transport byte 7 of the segmented 0x80 record.";
CM_ SG_ 133 ID85_B0 "Raw transport byte 0 of the segmented 0x85 record.";
CM_ SG_ 133 ID85_B1 "Raw transport byte 1 of the segmented 0x85 record.";
CM_ SG_ 133 ID85_B2 "Raw transport byte 2 of the segmented 0x85 record.";
CM_ SG_ 133 ID85_B3 "Raw transport byte 3 of the segmented 0x85 record.";
CM_ SG_ 133 ID85_B4 "Raw transport byte 4 of the segmented 0x85 record.";
CM_ SG_ 133 ID85_B5 "Raw transport byte 5 of the segmented 0x85 record.";
CM_ SG_ 133 ID85_B6 "Raw transport byte 6 of the segmented 0x85 record.";
CM_ SG_ 133 ID85_B7 "Raw transport byte 7 of the segmented 0x85 record.";
CM_ SG_ 129 A081_B0 "Always 0x30.";
CM_ SG_ 129 A081_B1 "Always zero.";
CM_ SG_ 129 A081_B2 "Always zero.";
CM_ SG_ 129 A081_B3 "Always zero.";
CM_ SG_ 129 A081_B4 "Always zero.";
CM_ SG_ 129 A081_B5 "Always zero.";
CM_ SG_ 129 A081_B6 "Always zero.";
CM_ SG_ 129 A081_B7 "Always zero.";
CM_ SG_ 134 A086_B0 "Always 0x30.";
CM_ SG_ 134 A086_B1 "Always zero.";
CM_ SG_ 134 A086_B2 "Always zero.";
CM_ SG_ 134 A086_B3 "Always zero.";
CM_ SG_ 134 A086_B4 "Always zero.";
CM_ SG_ 134 A086_B5 "Always zero.";
CM_ SG_ 134 A086_B6 "Always zero.";
CM_ SG_ 134 A086_B7 "Always zero.";
CM_ SG_ 256 A100_B0_STARTUP6 "Byte 0 bits 2-7: all ones in the first frame after power-up (with bytes 0-1 = FF FF), zero afterwards.";
CM_ SG_ 256 A100_PCS_ALARM "Pre-collision alarm (byte 0 = 0x02): 1 from the same CAN frame as the car-bus PCS alarm (0x283 PCSNOCHG, 0x411 FCW) until it ends; seen in 8 stock alarms on 7 cars (U3 and comma's fleet logs) and not otherwise apart from the power-up frame. Same as PCS_ALARM in the upstream DBC.";
CM_ SG_ 256 A100_B0_STARTUP1 "Byte 0 bit 0: 1 only in the first frame after power-up, zero afterwards.";
CM_ SG_ 256 A100_B1_STARTUP8 "0xFF in the first frame after power-up, zero afterwards.";
CM_ SG_ 256 A100_B2_B6_RESERVED_ZERO40 "Always zero.";
CM_ SG_ 257 A101_STARTUP_STATE8 "0x1D booting, 0x11 running (0x15 on the C-HR), 0x21 while the steering-wheel follow-distance switch is pressed (likely), 0x12 while the lane-departure-alert switch is pressed: the camera's LKAS_HUD changes 0.0-0.36 s later on 28 of 29 presses on 9 cars (LDA_SA_TOGGLE on 2023 RAV4s and the third car, LDA_ON_MESSAGE and the line display on 2022 RAV4s).";
CM_ SG_ 257 A101_B1_B5_RESERVED_ZERO40 "Always zero.";
CM_ SG_ 258 A102_B0_RESERVED_ZERO8 "0 on the RAV4s and the Yaris. On the C-HR camera (both opendbc test-route C-HRs) it is the running flag: 0x00 while booting (0x101 = 0x1D), 0x08 once running (0x101 = 0x15), on every log.";
CM_ SG_ 258 A102_B1_RESERVED_ZERO3 "0, except bit 9 = 1 during one EPS-unavailable start-up fault (second car), together with bit 21.";
CM_ SG_ 258 A102_CONTEXT_BIT11 "Copy of the camera's own LKAS_HUD (0x412) LDA_UNAVAILABLE: lane-departure alert unavailable. Stays set once the camera trips it, for example after engagement.";
CM_ SG_ 258 A102_B1_RESERVED4_5_ZERO2 "Always zero.";
CM_ SG_ 258 A102_CONTEXT_BIT14 "Camera state that the radar copies into its car-bus 0x366 report (byte 0 bit 1) a few hundred ms later; rises with short headway at speed (likely a close-following state).";
CM_ SG_ 258 A102_B1_RESERVED7_ZERO1 "Always zero.";
CM_ SG_ 258 A102_B2_RESERVED_ZERO5 "Always zero.";
CM_ SG_ 258 A102_CONTEXT_BIT21 "EPS steering assist unavailable: set while car-bus 0x262 EPS_STATUS LTA_STATE is 3 / 8 or LKA_STATE is 3, while the EPS is not yet initialised (LKA_STATE 0) or stops sending 0x262; clear in every other state (comma public fleet: 3,373 of 3,374 LTA_STATE-3 frames set, 5 transition frames in 4.67 M others). Follows the EPS within 0.05-0.2 s. Camera status, not radar data.";
CM_ SG_ 258 A102_B2_RESERVED6_7_ZERO2 "0, except bit 23 = 1 during one EPS-unavailable start-up fault (second car), together with bit 21.";
CM_ SG_ 259 A103_B0_RESERVED_ZERO8 "Always zero.";
CM_ SG_ 259 A103_B1_RESERVED_ZERO8 "Always zero.";
CM_ SG_ 1282 A502_B0_CONST8 "0x19 on most cars; 0x18 on the Yaris and on one 2022 RAV4 (the two vehicles whose 0x494 code also differs); 0x00 in start-up frames.";
CM_ SG_ 1282 A502_SLOW_CODE0_B1 "Slow estimator code (0x69-0x92 seen), +/-1 steps: stored across power cycles, frozen at standstill, paused in turns; meaning open.";
CM_ SG_ 1282 A502_SLOW_CODE1_BE16 "Slow estimator code (4308-4408 seen), big-endian: moves opposite to vehicle pitch (likely the elevation-alignment estimate, about 0.005-0.006 deg per code; docs/05).";
CM_ SG_ 1282 A502_TAIL_CONST_BE32 "Unit-specific constant (redacted here).";
CM_ SG_ 528 A210_RSA_SPEED_SIGN_PRESENT1 "Speed sign present: set for any speed-sign type in Toyota RSA1.TSGN1 (1, 32 or 36 seen), clear for 0.";
CM_ SG_ 528 A210_B0_RESERVED1_7 "Always zero.";
CM_ SG_ 528 A210_RSA_SPEED_LIMIT_VALUE8 "Speed-limit value (copy of Toyota RSA1.SPDVAL1; unit from RSA2.SPDUNT).";
CM_ SG_ 528 A210_B2 "Raw.";
CM_ SG_ 528 A210_B3 "Raw.";
CM_ SG_ 528 A210_B4 "Raw.";
CM_ SG_ 528 A210_B5_RESERVED0_5 "Always zero.";
CM_ SG_ 528 A210_RSA_MASTER_SWITCH1 "Road-sign-assist switch (copy of Toyota RSA3.TSRMSW).";
CM_ SG_ 528 A210_B5_STATUS_BIT7 "Startup / status bit.";
CM_ SG_ 528 A210_B6 "Raw.";
CM_ SG_ 514 A202_COUNTER4 "Counter mod 16, +1 per frame.";
CM_ SG_ 400 A190_TIMESTAMP_US "Radar cycle timestamp, microseconds (big-endian).";
CM_ SG_ 400 A190_COUNTER_RESERVED0 "Always zero.";
CM_ SG_ 400 A190_COUNTER4 "Cycle counter mod 16, +3 per cycle; use it to detect dropped cycles.";
CM_ SG_ 407 A197_STARTUP_PHASE1 "0 until about 0.2 s after the first object record, then 1 (stays 1 on the owner car and the Yaris, also through object-list outages, except while the camera reports itself unavailable, see A197_B1_RESERVED1_7; the 2022 RAV4 camera sets it for one frame or not at all). A boot flag, not live radar health.";
CM_ SG_ 407 A197_B1_RESERVED1_7 "0 normally; 3 (byte 1 = 0x06, with the boot bit cleared) while the camera function is temporarily unavailable: held through EPS steering-assist-unavailable minutes and seen as 0.1-1.5 s blips otherwise (comma public fleet, 2023 RAV4).";
CM_ SG_ 400 A190_STATUS_0_4 "Byte 0 low nibble: summary count << 2 | 2 (values 2, 6, 10).";
CM_ SG_ 400 A190_ACTIVE_SUMMARIES "Number of target summaries in this cycle (0-2): 0x191/0x192 fill first, then 0x193/0x194.";
CM_ SG_ 576 A240_B0_UNKNOWN5 "0 with the default body, 8 with a changing body.";
CM_ SG_ 576 A240_ROLLING_PHASE3 "Rolling phase 1-7 (0 at startup).";
CM_ SG_ 576 A240_RAW_WORD0_BE24 "Raw 24-bit big-endian view of three payload bytes.";
CM_ SG_ 576 A240_RAW_WORD1_BE24 "Raw 24-bit big-endian view of three payload bytes.";
CM_ SG_ 576 A240_B7_UNKNOWN8 "Raw.";
CM_ SG_ 577 A241_B0_RESERVED_ZERO5 "Always zero.";
CM_ SG_ 577 A241_ROLLING_PHASE3 "Rolling phase 1-7 (0 at startup).";
CM_ SG_ 577 A241_RAW_WORD0_BE24 "Raw 24-bit big-endian view of three payload bytes.";
CM_ SG_ 577 A241_RAW_WORD1_BE24 "Raw 24-bit big-endian view of three payload bytes.";
CM_ SG_ 577 A241_B7_RESERVED_ZERO8 "Always zero.";
CM_ SG_ 580 A244_B0_RESERVED_ZERO5 "Always zero.";
CM_ SG_ 580 A244_ROLLING_PHASE3 "Rolling phase 1-7 (0 at startup).";
CM_ SG_ 580 A244_RAW_WORD0_BE24 "Raw 24-bit big-endian view of three payload bytes.";
CM_ SG_ 580 A244_RAW_WORD1_BE24 "Raw 24-bit big-endian view of three payload bytes.";
CM_ SG_ 580 A244_B7_UNKNOWN8 "Raw.";
CM_ SG_ 581 A245_B0_RESERVED_ZERO5 "Always zero.";
CM_ SG_ 581 A245_ROLLING_PHASE3 "Rolling phase 1-7 (0 at startup).";
CM_ SG_ 581 A245_RAW_WORD0_BE24 "Raw 24-bit big-endian view of three payload bytes.";
CM_ SG_ 581 A245_RAW_WORD1_BE24 "Raw 24-bit big-endian view of three payload bytes.";
CM_ SG_ 581 A245_B7_RESERVED_ZERO8 "Always zero.";
CM_ SG_ 584 A248_B0_UNKNOWN2 "Raw.";
CM_ SG_ 584 A248_STARTUP_STATUS2 "Startup / status: 0 or 3.";
CM_ SG_ 584 A248_MUX_PHASE_RESERVED0 "Always zero.";
CM_ SG_ 584 A248_ROLLING_PHASE3 "Rolling phase 1-7 (0 at startup).";
CM_ SG_ 584 A248_B1_RESERVED_ZERO8 "Always zero.";
CM_ SG_ 584 A248_B2_STATE_BIT0 "Camera daylight state: 1 while its auto-high-beam status (0x414 C_AHB) is 7 (99.9 % on the comma public fleet); sets at start-up on daytime drives.";
CM_ SG_ 584 A248_B2_UNKNOWN1_7 "Raw.";
CM_ SG_ 584 A248_B3_B5_RESERVED_ZERO24 "Always zero.";
CM_ SG_ 584 A248_B6_UNKNOWN_BIT0 "Raw.";
CM_ SG_ 584 A248_EVENT_PULSE1 "Rare one-frame event pulse.";
CM_ SG_ 584 A248_B6_RESERVED2_6 "Always zero.";
CM_ SG_ 584 A248_B7_RESERVED_ZERO8 "Always zero.";
CM_ SG_ 1281 A501_B5_LOW3 "Low three bits: 4 in active recorded payloads; 0 in the startup payload.";
CM_ SG_ 1281 A501_STATUS_43_5 "Five-bit learned value in byte 5 bits 3-7, kept across drives (31 for 0.5 s, then 16 for 5.5 s after power-up), changed only while driving in single steps; adjacent-value steps include the 15/16 carry. Meaning open.";
CM_ SG_ 1664 A680_SELECTOR "0 / 1 mostly stationary objects, 3 mostly same-direction vehicles.";
CM_ SG_ 1664 A680_LONG_DIST "Longitudinal distance; stationary objects close at ego speed with 32 codes per metre.";
CM_ SG_ 1664 A680_LAT_DIST "Lateral position, left positive, 0.015 m per code (the object list's lateral unit).";
CM_ SG_ 1664 A680_SPEED_OVER_GROUND "Speed over ground, nominal unit; 0 for stationary objects.";
CM_ SG_ 1664 A680_FLAGS "Motion flags: bit 0 stationary, bit 1 oncoming, bit 3 seen moving; bits 2, 4, 5 raw. 1 = stationary object, 8 = moving vehicle, 9 = stopped vehicle.";
CM_ SG_ 1664 A680_STATIONARY "Flag bit 0: set on 99 % of objects slower than 0.5 m/s over ground and on 1 % of moving ones.";
CM_ SG_ 1664 A680_ONCOMING "Flag bit 1: set on 98 % of objects faster than 3 m/s toward ego and on 1 % of the others.";
CM_ SG_ 1664 A680_SEEN_MOVING "Flag bit 3: set on 86 % of same-direction moving objects and 10 % of stationary ones (with bit 0: a stopped vehicle).";
CM_ SG_ 1664 A680_LAT_SPEED_CODE "Lateral speed over ground, left positive, about 0.13-0.18 m/s per code (0.15 nominal); 0 on stationary objects.";
CM_ SG_ 1664 A680_B7_HIGH4 "14 on most frames.";
CM_ SG_ 1664 A680_B7_LOW4 "0xA with selector 0, 0xF with selector 1 / 3.";
CM_ SG_ 401 A191_B0_RESERVED0 "Always zero.";
CM_ SG_ 401 A191_PAIR_SCORE_CODE7 "Target score: 91-100 while active, rising with the target's own over-ground speed (100 above about 15 m/s) and slightly with track maturity: a moving-vehicle confidence, not a speed; 127 in the sentinel.";
CM_ SG_ 401 A191_B1_RESERVED0 "Always zero.";
CM_ SG_ 401 A191_PAIR_TRACK_AGE7 "Target age in radar cycles, saturates at 126; 127 in the sentinel.";
CM_ SG_ 401 A191_B3_RESERVED0_2 "Always zero.";
CM_ SG_ 401 A191_PAIR_TRACK_ID6 "Target track code; a code can move between the A (0x191) and B (0x193) pairs.";
CM_ SG_ 401 A191_B4_RESERVED0_2 "Always zero.";
CM_ SG_ 401 A191_PAIR_DESCRIPTOR0_CODE6 "Class template width, m: 1.8 car, 2.2 truck (the class on 0x239 when this is the ACC target); rare other values 2.5-3.0.";
CM_ SG_ 401 A191_B5_RESERVED0_3 "Zero in practice (seen as 4 once, one frame before a sentinel).";
CM_ SG_ 401 A191_PAIR_FIELD5_CODE5 "Counter that grows with target age and saturates at 30 (31 in the sentinel).";
CM_ SG_ 401 A191_B6_RESERVED0 "Always zero.";
CM_ SG_ 401 A191_PAIR_DESCRIPTOR1_CODE7 "Class template height-like size, m: 1.5 car, 2.3 truck.";
CM_ SG_ 401 A191_PAIR_DESCRIPTOR2_CODE8 "Class template length, m: 4.5 car, 12.0 truck; rare other values from 2.0.";
CM_ SG_ 402 A192_WORD0_RESERVED_ZERO3 "Always zero.";
CM_ SG_ 402 A192_PAIR_RANGE_CODE13 "Distance of one internal-tracker target: (code - 160) / 16 m, the object list encoding.";
CM_ SG_ 402 A192_WORD1_RESERVED_ZERO3 "Zero, except bit 21 = 1 on five frames of one drive while the lateral field held a far-right target near its floor (-30.7 to -23.8 m): possibly a range marker or extension of the lateral field.";
CM_ SG_ 402 A192_PAIR_FIELD1_CODE13 "Lateral position of the same target: (code - 2048) * 0.015 m, left positive; keep all 13 bits.";
CM_ SG_ 403 A193_B0_RESERVED0 "Always zero.";
CM_ SG_ 403 A193_PAIR_SCORE_CODE7 "Target score: 91-100 while active, rising with the target's own over-ground speed (100 above about 15 m/s) and slightly with track maturity: a moving-vehicle confidence, not a speed; 127 in the sentinel.";
CM_ SG_ 403 A193_B1_RESERVED0 "Always zero.";
CM_ SG_ 403 A193_PAIR_TRACK_AGE7 "Target age in radar cycles, saturates at 126; 127 in the sentinel.";
CM_ SG_ 403 A193_B3_RESERVED0_2 "Always zero.";
CM_ SG_ 403 A193_PAIR_TRACK_ID6 "Target track code; a code can move between the A (0x191) and B (0x193) pairs.";
CM_ SG_ 403 A193_B4_RESERVED0_2 "Always zero.";
CM_ SG_ 403 A193_PAIR_DESCRIPTOR0_CODE6 "Class template width, m: 1.8 car, 2.2 truck.";
CM_ SG_ 403 A193_B5_RESERVED0_3 "Zero; 7 in the sentinel.";
CM_ SG_ 403 A193_PAIR_FIELD5_CODE5 "Counter that grows with target age and saturates at 30 (31 in the sentinel).";
CM_ SG_ 403 A193_B6_RESERVED0 "Always zero.";
CM_ SG_ 403 A193_PAIR_DESCRIPTOR1_CODE7 "Class template height-like size, m: 1.5 car, 2.3 truck.";
CM_ SG_ 403 A193_PAIR_DESCRIPTOR2_CODE8 "Class template length, m: 4.5 car, 12.0 truck.";
CM_ SG_ 404 A194_WORD0_RESERVED_ZERO3 "Zero, apart from the rare all-ones (FF ...) frames.";
CM_ SG_ 404 A194_PAIR_RANGE_CODE13 "Distance of one internal-tracker target: (code - 160) / 16 m, the object list encoding.";
CM_ SG_ 404 A194_WORD1_RESERVED_ZERO3 "Zero, apart from the rare all-ones (FF ...) frames.";
CM_ SG_ 404 A194_PAIR_FIELD1_CODE13 "Lateral position of the same target: (code - 2048) * 0.015 m, left positive; keep all 13 bits.";
CM_ SG_ 565 CHECK_BYTE "CRC-8 (polynomial 0x1D, MSB first) over the frame's signals serialized as zero-padded 8 / 16 / 32-bit integers, not over the raw bytes; as a 56-column table in ars510.support.acc_check (docs/05).";
CM_ SG_ 565 STATE "5 with an ACC target, 1 without (idle payload), 15 at start-up.";
CM_ SG_ 565 COUNTER "Rolling counter.";
CM_ SG_ 567 CHECK_BYTE "CRC-8 (polynomial 0x1D, MSB first) over the frame's signals serialized as zero-padded 8 / 16 / 32-bit integers, not over the raw bytes; as a 56-column table in ars510.support.acc_check (docs/05).";
CM_ SG_ 567 COUNTER "Rolling counter.";
CM_ SG_ 569 CHECK_BYTE "CRC-8 (polynomial 0x1D, MSB first) over the frame's signals serialized as zero-padded 8 / 16 / 32-bit integers, not over the raw bytes; as a 56-column table in ars510.support.acc_check (docs/05).";
CM_ SG_ 569 CLASS "ACC target class: 1 car, 2 truck (the 0x191 template class), 0 narrow stationary object, 6 wide stationary object, 4 unclassified object, 5 crossing object, 7 idle; 3 not seen.";
CM_ SG_ 569 IN_OBJECT_LIST "1 while the ACC target also has an object in the 0x80 list.";
CM_ SG_ 569 PRESENT "1 with an ACC target.";
CM_ SG_ 569 TIMESTAMP "Radar cycle clock of this target update, microseconds (advances once per 60 ms cycle, with or without a target), on the 0x190 clock: equal to A190_TIMESTAMP_US in 73 % of frames, within one cycle in 99.8 %.";
CM_ SG_ 569 COUNTER "Rolling counter.";
CM_ SG_ 571 A23B_B0_CHECK_BYTE "Check byte: CRC-8 SAE J1850 (poly 0x1D, init 0xFF, final xor 0xFF) over the bytes 0x00, counter, width as 16 bits. Startup frames 00 0F FF differ.";
CM_ SG_ 571 A23B_STATUS_MUX4 "Byte-1 low nibble: high bits of the target width (1 for widths of 256 cm and more).";
CM_ SG_ 571 A23B_TARGET_WIDTH_CM "Width of the ACC target, cm: 0 without a target, 140-220 for the car class (median 171), 200-280 for the truck class.";
CM_ SG_ 571 A23B_COUNTER4 "Rolling counter.";
VAL_ 257 A101_STARTUP_STATE8 29 "startup_0x1D" 17 "post_startup_base_0x11" 33 "fd_switch_pressed_0x21" 18 "lda_switch_pressed_0x12" 21 "chr_running_0x15" ;
VAL_ 258 A102_CONTEXT_BIT11 0 "STATE_0x0" 1 "STATE_0x1" ;
VAL_ 258 A102_CONTEXT_BIT14 0 "STATE_0x0" 1 "STATE_0x1" ;
VAL_ 258 A102_CONTEXT_BIT21 0 "STATE_0x0" 1 "STATE_0x1" ;
VAL_ 400 A190_STATUS_0_4 0 "STATE_0x0" 1 "STATE_0x1" 2 "STATE_0x2" 3 "STATE_0x3" 4 "STATE_0x4" 5 "STATE_0x5" 6 "STATE_0x6" 7 "STATE_0x7" 8 "STATE_0x8" 9 "STATE_0x9" 10 "STATE_0xA" 11 "STATE_0xB" 12 "STATE_0xC" 13 "STATE_0xD" 14 "STATE_0xE" 15 "STATE_0xF" ;
VAL_ 400 A190_COUNTER4 0 "COUNT_0x0" 1 "COUNT_0x1" 2 "COUNT_0x2" 3 "COUNT_0x3" 4 "COUNT_0x4" 5 "COUNT_0x5" 6 "COUNT_0x6" 7 "COUNT_0x7" 8 "COUNT_0x8" 9 "COUNT_0x9" 10 "COUNT_0xA" 11 "COUNT_0xB" 12 "COUNT_0xC" 13 "COUNT_0xD" 14 "COUNT_0xE" 15 "COUNT_0xF" ;
VAL_ 407 A197_STARTUP_PHASE1 0 "STATE_0x0" 1 "STATE_0x1" ;
VAL_ 514 A202_COUNTER4 0 "COUNT_0x0" 1 "COUNT_0x1" 2 "COUNT_0x2" 3 "COUNT_0x3" 4 "COUNT_0x4" 5 "COUNT_0x5" 6 "COUNT_0x6" 7 "COUNT_0x7" 8 "COUNT_0x8" 9 "COUNT_0x9" 10 "COUNT_0xA" 11 "COUNT_0xB" 12 "COUNT_0xC" 13 "COUNT_0xD" 14 "COUNT_0xE" 15 "COUNT_0xF" ;
VAL_ 528 A210_RSA_SPEED_SIGN_PRESENT1 0 "STATE_0x0" 1 "STATE_0x1" ;
VAL_ 528 A210_RSA_MASTER_SWITCH1 0 "STATE_0x0" 1 "STATE_0x1" ;
VAL_ 528 A210_B5_STATUS_BIT7 0 "STATE_0x0" 1 "STATE_0x1" ;
VAL_ 576 A240_ROLLING_PHASE3 0 "STATE_0x0" 1 "STATE_0x1" 2 "STATE_0x2" 3 "STATE_0x3" 4 "STATE_0x4" 5 "STATE_0x5" 6 "STATE_0x6" 7 "STATE_0x7" ;
VAL_ 577 A241_ROLLING_PHASE3 0 "STATE_0x0" 1 "STATE_0x1" 2 "STATE_0x2" 3 "STATE_0x3" 4 "STATE_0x4" 5 "STATE_0x5" 6 "STATE_0x6" 7 "STATE_0x7" ;
VAL_ 580 A244_ROLLING_PHASE3 0 "STATE_0x0" 1 "STATE_0x1" 2 "STATE_0x2" 3 "STATE_0x3" 4 "STATE_0x4" 5 "STATE_0x5" 6 "STATE_0x6" 7 "STATE_0x7" ;
VAL_ 581 A245_ROLLING_PHASE3 0 "STATE_0x0" 1 "STATE_0x1" 2 "STATE_0x2" 3 "STATE_0x3" 4 "STATE_0x4" 5 "STATE_0x5" 6 "STATE_0x6" 7 "STATE_0x7" ;
VAL_ 584 A248_STARTUP_STATUS2 0 "STATE_0x0" 1 "STATE_0x1" 2 "STATE_0x2" 3 "STATE_0x3" ;
VAL_ 584 A248_ROLLING_PHASE3 0 "STATE_0x0" 1 "STATE_0x1" 2 "STATE_0x2" 3 "STATE_0x3" 4 "STATE_0x4" 5 "STATE_0x5" 6 "STATE_0x6" 7 "STATE_0x7" ;
VAL_ 584 A248_B2_STATE_BIT0 0 "STATE_0x0" 1 "STATE_0x1" ;
VAL_ 584 A248_EVENT_PULSE1 0 "STATE_0x0" 1 "STATE_0x1" ;
VAL_ 591 A24F_STARTUP_PHASE1 0 "STATE_0x0" 1 "STATE_0x1" ;
VAL_ 569 CLASS 0 "OTHER_0" 1 "CAR" 2 "TRUCK" 4 "OTHER_4" 5 "OTHER_5" 6 "OTHER_6" 7 "NO_TARGET" 15 "STARTUP" ;
VAL_ 571 A23B_STATUS_MUX4 0 "STATE_0x0" 1 "STATE_0x1" 2 "STATE_0x2" 3 "STATE_0x3" 4 "STATE_0x4" 5 "STATE_0x5" 6 "STATE_0x6" 7 "STATE_0x7" 8 "STATE_0x8" 9 "STATE_0x9" 10 "STATE_0xA" 11 "STATE_0xB" 12 "STATE_0xC" 13 "STATE_0xD" 14 "STATE_0xE" 15 "STATE_0xF" ;
VAL_ 571 A23B_COUNTER4 0 "COUNT_0x0" 1 "COUNT_0x1" 2 "COUNT_0x2" 3 "COUNT_0x3" 4 "COUNT_0x4" 5 "COUNT_0x5" 6 "COUNT_0x6" 7 "COUNT_0x7" 8 "COUNT_0x8" 9 "COUNT_0x9" 10 "COUNT_0xA" 11 "COUNT_0xB" 12 "COUNT_0xC" 13 "COUNT_0xD" 14 "COUNT_0xE" 15 "COUNT_0xF" ;
VAL_ 565 STATE 15 "STARTUP" 5 "TARGET" 1 "NO_TARGET" ;
